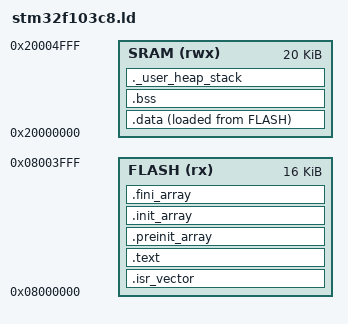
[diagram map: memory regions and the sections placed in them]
ENTRY(Reset_Handler)

MEMORY
{
  FLASH (rx)  : ORIGIN = 0x08000000, LENGTH = 16K
  SRAM  (rwx) : ORIGIN = 0x20000000, LENGTH = 20K
}

_estack = ORIGIN(SRAM) + LENGTH(SRAM);

SECTIONS
{
  .isr_vector :
  {
    KEEP(*(.isr_vector))
  } > FLASH

  .text :
  {
    *(.text*)
    *(.rodata*)
    *(.glue_7)
    *(.glue_7t)
    KEEP(*(.init))
    KEEP(*(.fini))
  } > FLASH

  . = ALIGN(4);
  .preinit_array :
  {
    PROVIDE_HIDDEN(__preinit_array_start = .);
    KEEP(*(.preinit_array*))
    PROVIDE_HIDDEN(__preinit_array_end = .);
  } > FLASH

  . = ALIGN(4);
  .init_array :
  {
    PROVIDE_HIDDEN(__init_array_start = .);
    KEEP(*(SORT(.init_array.*)))
    KEEP(*(.init_array*))
    PROVIDE_HIDDEN(__init_array_end = .);
  } > FLASH

  . = ALIGN(4);
  .fini_array :
  {
    PROVIDE_HIDDEN(__fini_array_start = .);
    KEEP(*(SORT(.fini_array.*)))
    KEEP(*(.fini_array*))
    PROVIDE_HIDDEN(__fini_array_end = .);
  } > FLASH

  _sidata = LOADADDR(.data);
  _etext = .;

  .data :
  {
    _sdata = .;
    *(.data*)
    _edata = .;
  } > SRAM AT> FLASH

  .bss :
  {
    _sbss = .;
    *(.bss*)
    *(COMMON)
    _ebss = .;
  } > SRAM

  /* ===== Heap & Stack ===== */

  ._user_heap_stack :
  {
    . = ALIGN(8);
    _end = .;
    PROVIDE(end = .);

    . = . + 0x400;   /* 1KB heap */
    . = ALIGN(8);
  } > SRAM
}
